# ESP32 register map
Vendor: ESPRESSIF SYSTEMS (SHANGHAI) CO., LTD.; Series: ESP32 Series; File version: 17
CPU: Xtensa LX6 r0p0, little endian, no MPU, FPU, 0 interrupt priority bits
Address unit: 32 bits
Registers are 32-bit, read-write, reset 0x0 unless marked. A register's access mark holds for its fields unless they carry their own. Offsets are from the block's base; [hi:lo] are bit positions; {n}, {i} and the like mark numbered series.

## EFUSE — eFuse Controller
Base 0x3FF5A000
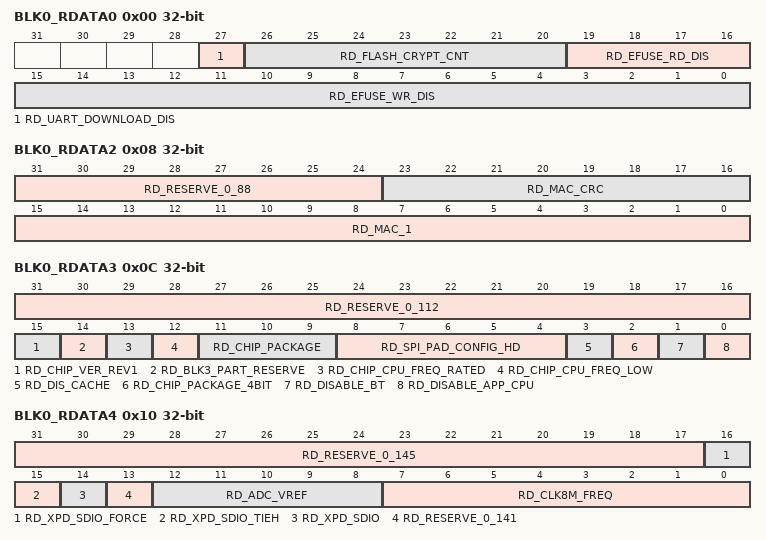
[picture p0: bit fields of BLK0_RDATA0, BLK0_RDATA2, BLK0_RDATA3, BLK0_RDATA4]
0x00 BLK0_RDATA0 ro
  [27] RD_UART_DOWNLOAD_DIS, [26:20] RD_FLASH_CRYPT_CNT, [19:16] RD_EFUSE_RD_DIS, [15:0] RD_EFUSE_WR_DIS
0x04 BLK0_RDATA1 ro
  [31:0] RD_MAC
0x08 BLK0_RDATA2 access per field
  [31:24] RD_RESERVE_0_88 rw, [23:16] RD_MAC_CRC ro, [15:0] RD_MAC_1 ro
0x0C BLK0_RDATA3 access per field
  [31:16] RD_RESERVE_0_112 rw, [15] RD_CHIP_VER_REV1 rw, [14] RD_BLK3_PART_RESERVE rw, [13] RD_CHIP_CPU_FREQ_RATED rw, [12] RD_CHIP_CPU_FREQ_LOW rw, [11:9] RD_CHIP_PACKAGE rw, [8:4] RD_SPI_PAD_CONFIG_HD ro, [3] RD_DIS_CACHE ro, [2] RD_CHIP_PACKAGE_4BIT ro, [1] RD_DISABLE_BT ro, [0] RD_DISABLE_APP_CPU ro
0x10 BLK0_RDATA4 access per field
  [31:17] RD_RESERVE_0_145 rw, [16] RD_XPD_SDIO_FORCE ro, [15] RD_XPD_SDIO_TIEH ro, [14] RD_XPD_SDIO ro, [13] RD_RESERVE_0_141 rw, [12:8] RD_ADC_VREF rw, [7:0] RD_CLK8M_FREQ ro
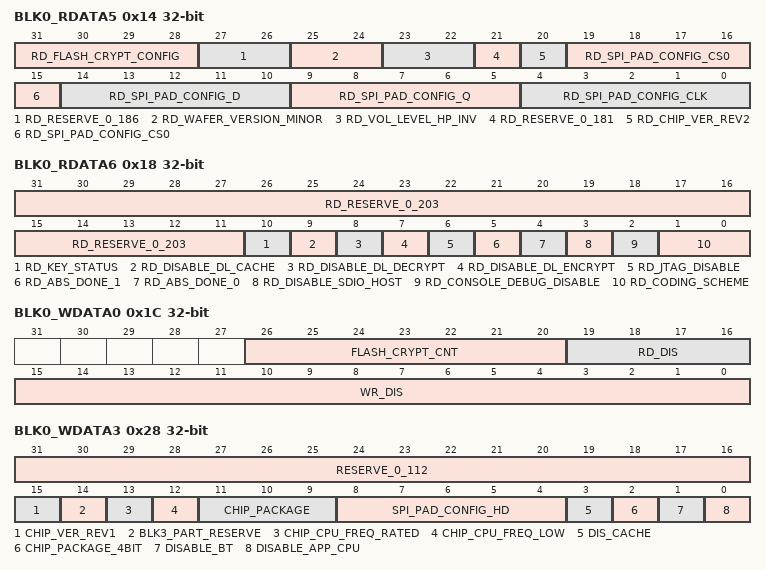
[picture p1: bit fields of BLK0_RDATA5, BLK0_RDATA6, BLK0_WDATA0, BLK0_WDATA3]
0x14 BLK0_RDATA5 access per field
  [31:28] RD_FLASH_CRYPT_CONFIG ro, [27:26] RD_RESERVE_0_186 rw, [25:24] RD_WAFER_VERSION_MINOR ro, [23:22] RD_VOL_LEVEL_HP_INV ro, [21] RD_RESERVE_0_181 rw, [20] RD_CHIP_VER_REV2 ro, [19:15] RD_SPI_PAD_CONFIG_CS0 ro, [14:10] RD_SPI_PAD_CONFIG_D ro, [9:5] RD_SPI_PAD_CONFIG_Q ro, [4:0] RD_SPI_PAD_CONFIG_CLK ro
0x18 BLK0_RDATA6 access per field
  [31:11] RD_RESERVE_0_203 rw, [10] RD_KEY_STATUS ro, [9] RD_DISABLE_DL_CACHE ro, [8] RD_DISABLE_DL_DECRYPT ro, [7] RD_DISABLE_DL_ENCRYPT ro, [6] RD_JTAG_DISABLE ro, [5] RD_ABS_DONE_1 ro, [4] RD_ABS_DONE_0 ro, [3] RD_DISABLE_SDIO_HOST ro, [2] RD_CONSOLE_DEBUG_DISABLE ro, [1:0] RD_CODING_SCHEME ro
0x1C BLK0_WDATA0
  [26:20] FLASH_CRYPT_CNT, [19:16] RD_DIS, [15:0] WR_DIS
0x20 BLK0_WDATA1
  [31:0] WIFI_MAC_CRC_LOW
0x24 BLK0_WDATA2
  [23:0] WIFI_MAC_CRC_HIGH
0x28 BLK0_WDATA3 access per field
  [31:16] RESERVE_0_112 rw, [15] CHIP_VER_REV1 rw, [14] BLK3_PART_RESERVE rw, [13] CHIP_CPU_FREQ_RATED rw, [12] CHIP_CPU_FREQ_LOW rw, [11:9] CHIP_PACKAGE rw, [8:4] SPI_PAD_CONFIG_HD ro, [3] DIS_CACHE ro, [2] CHIP_PACKAGE_4BIT ro, [1] DISABLE_BT ro, [0] DISABLE_APP_CPU ro
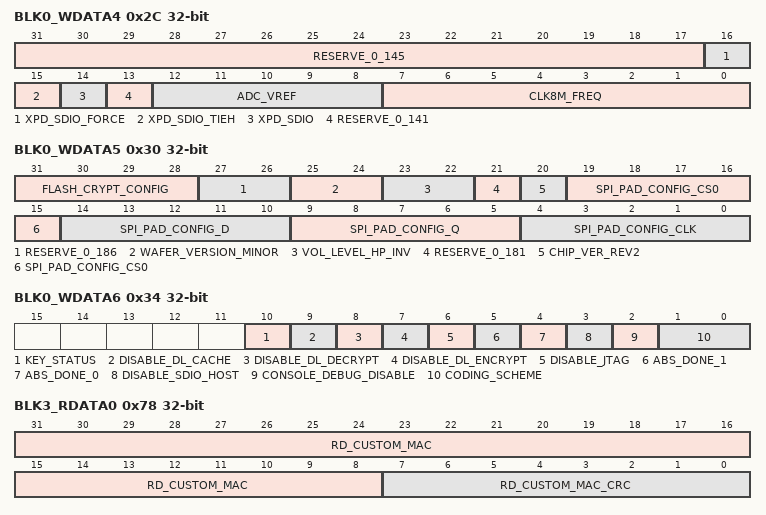
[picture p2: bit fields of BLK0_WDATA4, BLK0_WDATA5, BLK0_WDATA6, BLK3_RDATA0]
0x2C BLK0_WDATA4 access per field
  [31:17] RESERVE_0_145 rw, [16] XPD_SDIO_FORCE ro, [15] XPD_SDIO_TIEH ro, [14] XPD_SDIO ro, [13] RESERVE_0_141 rw, [12:8] ADC_VREF rw, [7:0] CLK8M_FREQ ro
0x30 BLK0_WDATA5 access per field
  [31:28] FLASH_CRYPT_CONFIG ro, [27:26] RESERVE_0_186 rw, [25:24] WAFER_VERSION_MINOR ro, [23:22] VOL_LEVEL_HP_INV ro, [21] RESERVE_0_181 rw, [20] CHIP_VER_REV2 ro, [19:15] SPI_PAD_CONFIG_CS0 ro, [14:10] SPI_PAD_CONFIG_D ro, [9:5] SPI_PAD_CONFIG_Q ro, [4:0] SPI_PAD_CONFIG_CLK ro
0x34 BLK0_WDATA6
  [10] KEY_STATUS, [9] DISABLE_DL_CACHE, [8] DISABLE_DL_DECRYPT, [7] DISABLE_DL_ENCRYPT, [6] DISABLE_JTAG, [5] ABS_DONE_1, [4] ABS_DONE_0, [3] DISABLE_SDIO_HOST, [2] CONSOLE_DEBUG_DISABLE, [1:0] CODING_SCHEME
0x38 BLK1_RDATA0 ro
  [31:0] RD_BLOCK1
{0x38+4i} BLK1_RDATA{i} ro (i=1..7)
  [31:0] RD_BLOCK1_{i}
0x58 BLK2_RDATA0 ro
  [31:0] RD_BLOCK2
{0x58+4i} BLK2_RDATA{i} ro (i=1..7)
  [31:0] RD_BLOCK2_{i}
0x78 BLK3_RDATA0 ro
  [31:8] RD_CUSTOM_MAC, [7:0] RD_CUSTOM_MAC_CRC
0x7C BLK3_RDATA1 ro
  [23:0] RD_CUSTOM_MAC_1
0x80 BLK3_RDATA2 ro
  [31:0] RD_BLK3_RESERVED_2
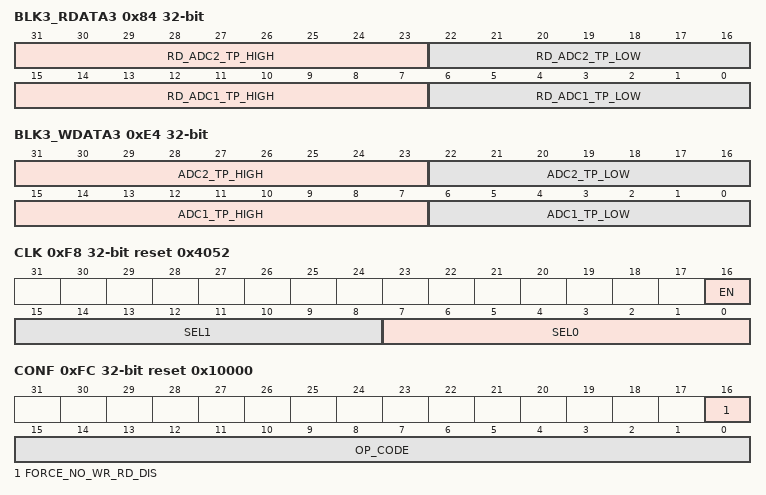
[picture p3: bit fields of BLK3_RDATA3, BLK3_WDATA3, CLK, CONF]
0x84 BLK3_RDATA3
  [31:23] RD_ADC2_TP_HIGH, [22:16] RD_ADC2_TP_LOW, [15:7] RD_ADC1_TP_HIGH, [6:0] RD_ADC1_TP_LOW
0x88 BLK3_RDATA4 ro
  [31:0] RD_SECURE_VERSION
0x8C BLK3_RDATA5 ro
  [31:24] RD_MAC_VERSION
0x90 BLK3_RDATA6 ro
  [31:0] RD_BLK3_RESERVED_6
0x94 BLK3_RDATA7 ro
  [31:0] RD_BLK3_RESERVED_7
{0x98+4i} BLK1_WDATA{i} (i=0..7)
  [31:0] BLK1_DIN{i}
{0xB8+4i} BLK2_WDATA{i} (i=0..7)
  [31:0] BLK2_DIN{i}
{0xD8+4i} BLK3_WDATA{i} (i=0..2)
  [31:0] BLK3_DIN{i}
0xE4 BLK3_WDATA3
  [31:23] ADC2_TP_HIGH, [22:16] ADC2_TP_LOW, [15:7] ADC1_TP_HIGH, [6:0] ADC1_TP_LOW
0xE8 BLK3_WDATA4 ro
  [31:0] SECURE_VERSION
{0xD8+4i} BLK3_WDATA{i} (i=5..7)
  [31:0] BLK3_DIN{i}
0xF8 CLK reset 0x4052
  [16] EN, [15:8] SEL1, [7:0] SEL0
0xFC CONF reset 0x10000
  [16] FORCE_NO_WR_RD_DIS, [15:0] OP_CODE
0x100 STATUS ro
  [31:0] DEBUG
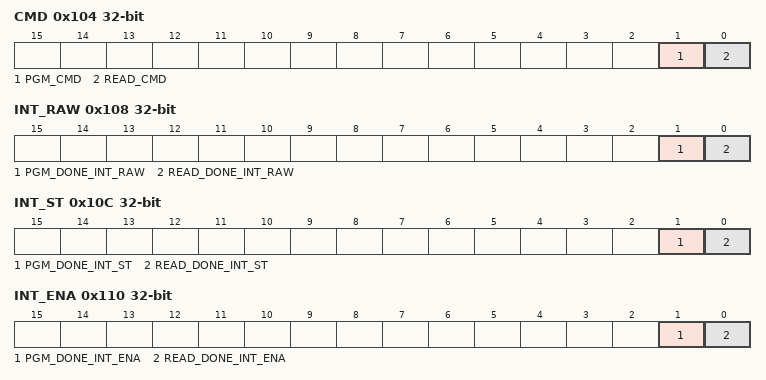
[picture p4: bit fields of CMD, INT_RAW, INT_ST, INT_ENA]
0x104 CMD
  [1] PGM_CMD, [0] READ_CMD
0x108 INT_RAW ro
  [1] PGM_DONE_INT_RAW, [0] READ_DONE_INT_RAW
0x10C INT_ST ro
  [1] PGM_DONE_INT_ST, [0] READ_DONE_INT_ST
0x110 INT_ENA
  [1] PGM_DONE_INT_ENA, [0] READ_DONE_INT_ENA
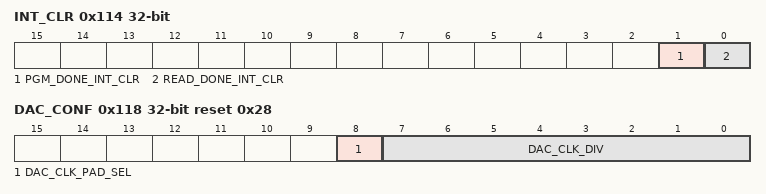
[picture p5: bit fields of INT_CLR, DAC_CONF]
0x114 INT_CLR wo
  [1] PGM_DONE_INT_CLR, [0] READ_DONE_INT_CLR
0x118 DAC_CONF reset 0x28
  [8] DAC_CLK_PAD_SEL, [7:0] DAC_CLK_DIV
0x11C DEC_STATUS ro
  [11:0] DEC_WARNINGS
0x1FC DATE reset 0x16042600
